# nrf54lv10a_application register map
Vendor: Nordic Semiconductor; Series: nrf54l; File version: 1
CPU: CM33 r0p4, little endian, MPU, FPU, 3 interrupt priority bits, 270 interrupts, 4 SAU regions
Registers are 32-bit, read-write, reset 0x0 unless marked. A register's access mark holds for its fields unless they carry their own. Offsets are from the block's base; [hi:lo] are bit positions; lines under a group give offsets from that group.

## GLOBAL_RESET_NS — Reset control 0
Base 0x4010E000; alternate view of GLOBAL_CLOCK_NS
Same registers: GLOBAL_RESET_S 0x5010E000 (alternate view of GLOBAL_CLOCK_S)
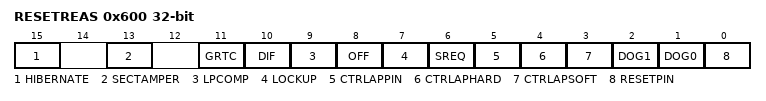
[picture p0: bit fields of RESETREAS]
0x600 RESETREAS — Reset reason
  [all] fields
    0=NotDetected; 1=Detected
  [15] HIBERNATE — Reset after wakeup from Hibernate mode
  [13] SECTAMPER — Reset due to illegal tampering of the device
  [11] GRTC — Reset due to wakeup from GRTC
  [10] DIF — Reset triggered by Debug Interface
  [9] LPCOMP — Reset due to wakeup from System OFF mode when wakeup is triggered by ANADETECT signal from LPCOMP
  [8] OFF — Reset due to wakeup from System OFF mode when wakeup is triggered by DETECT signal from GPIO
  [7] LOCKUP — Reset from CPU lockup detected
  [6] SREQ — Reset from soft reset detected
  [5] CTRLAPPIN — Reset due to CTRL-AP pin reset
  [4] CTRLAPHARD — Reset due to CTRL-AP hard reset
  [3] CTRLAPSOFT — Soft reset from CTRL-AP detected
  [2] DOG1 — Reset from watchdog timer 1 detected
  [1] DOG0 — Reset from watchdog timer 0 detected
  [0] RESETPIN — Reset from pin reset detected

## GLOBAL_OSCILLATORS_NS — Oscillator control 0
Base 0x40120000
Same registers: GLOBAL_OSCILLATORS_S 0x50120000
0x700 XOSC32M group — 32 MHz oscillator control
  0x14 CONFIG group — Unspecified
    0x08 INTCAP reset 0x20 — Crystal load capacitor as seen by the crystal across its terminals, including pin capacitance but excluding PCB stray capacitance.
      [5:0] VAL — Crystal load capacitor value
0x800 PLL group — Oscillator control
  0x00 FREQ reset 0x3 — Set speed of MCU power domain, including CPU
    [1:0] FREQ — Select CPU speed
      1=CK128M (128 MHz); 3=CK64M (64 MHz)
  0x04 CURRENTFREQ ro reset 0x3 — Current speed of MCU power domain, including CPU
    [1:0] CURRENTFREQ — Active CPU speed
      1=CK128M (128 MHz); 3=CK64M (64 MHz)
0x900 XOSC32KI group — 32.768 kHz oscillator control
  0x00 BYPASS — Enable or disable bypass of LFCLK crystal oscillator with external clock source
    [0] BYPASS
      0=Disabled (Disable (use crystal)); 1=Enabled (Enable (use rail-to-rail external source))
  0x04 INTCAP reset 0x17 — Programmable capacitance of XL1 and XL2
    [4:0] VAL — Crystal load capacitor as seen by the crystal across its terminals, including pin capacitance but excluding PCB stray capacitance.
  0x14 STATUS ro — Status information
    [2] CLOCKRUNNING — Clock status
      0=NotRunning (Clock is not running.); 1=Running (Clock is running.)

## GLOBAL_REGULATORS_NS — Voltage regulators 0
Base 0x40120000; alternate view of GLOBAL_OSCILLATORS_NS
Same registers: GLOBAL_REGULATORS_S 0x50120000 (alternate view of GLOBAL_OSCILLATORS_S)
0x400 HIBERNATOR group — Hibernator interface
  0x00 SYSTEMHIBERNATE wo — Enter System hibernation mode for extreme low power consumption
    [0] SYSTEMHIBERNATE — Enter hibernation mode
      1=Enter hibernation mode
  0x04 GPIORETENTIONRELEASE — Release GPIO retention on wake up from hibernation mode.
    [0] GPIORETENTIONRELEASE — Release GPIO retention
      0=NoRelease (Do not release retention); 1=Release retention
  0x08 GPIORETENTIONSTATUS ro — Read out if GPIO retention is active.
    [0] GPIORETENTIONSTATUS
      0=NotActive (GPIO retention is not active.); 1=Active (GPIO retention is active.)
0x500 SYSTEMOFF wo
  [0] SYSTEMOFF — Enable System OFF mode
    1=Enter (Enable System OFF mode)
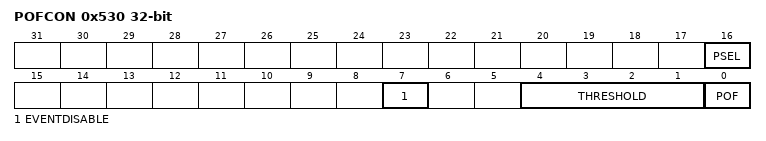
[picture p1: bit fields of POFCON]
0x530 POFCON — Power-fail comparator configuration
  [16] PSEL — Power-fail comparator input selector
    1=VddL (POF input connected to VDDL)
  [7] EVENTDISABLE — Disable the POFWARN power-fail warning event
    0=Enabled (POFWARN event is generated); 1=Disabled (POFWARN event is not generated)
  [4:1] THRESHOLD — Power-fail comparator threshold setting
    0=V090 (Set threshold to 0.90 V for VDDL); 1=V095 (Set threshold to 0.95 V for VDDL); 2=V100 (Set threshold to 1.00 V for VDDL); 3=V105 (Set threshold to 1.05 V for VDDL); 4=V110 (Set threshold to 1.10 V for VDDL); 5=V115 (Set threshold to 1.15 V for VDDL); 6=V120 (Set threshold to 1.20 V for VDDL); 7=V125 (Set threshold to 1.25 V for VDDL); 8=V130 (Set threshold to 1.30 V for VDDL); 9=V135 (Set threshold to 1.35 V for VDDL); 10=V140 (Set threshold to 1.40 V for VDDL); 11=V145 (Set threshold to 1.45 V for VDDL); 12=V150 (Set threshold to 1.50 V for VDDL); 13=V155 (Set threshold to 1.55 V for VDDL); 14=V160 (Set threshold to 1.60 V for VDDL); 15=V165 (Set threshold to 1.65 V for VDDL)
  [0] POF — Enable or disable power-fail comparator
    0=Disabled; 1=Enabled
0x534 POFSTAT ro — Power-fail comparator status register
  [0] COMPARATOR — Power-fail comparator status
    0=Above (Voltage detected above VPOF threshold); 1=Below (Voltage detected below VPOF threshold)
0x600 VREGMAIN group — Register interface for main voltage regulator.
  0x00 DCDCEN — Enable DC/DC converter
    [0] VAL — Enable DC/DC buck converter
      0=Disable DC/DC buck converter; 1=Enable DC/DC converter
  0x04 INDUCTORDET ro — VREGMAIN inductor detection
    [0] DETECTED
      0=InductorNotDetected (VREGMAIN inductor not detected); 1=InductorDetected (VREGMAIN inductor detected)
